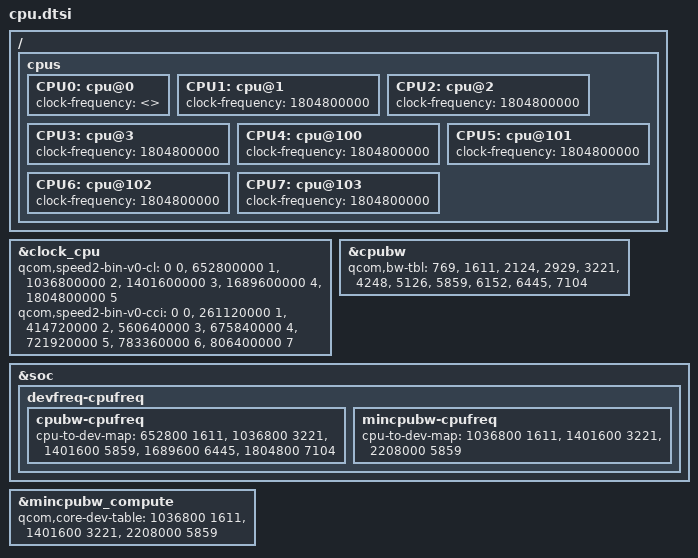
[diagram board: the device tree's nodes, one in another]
/{
	cpus {
        CPU0: cpu@0 {
    			clock-frequency = <>;
  		};
        CPU1: cpu@1 {
    			clock-frequency = <1804800000>;
  		};
        CPU2: cpu@2 {
    			clock-frequency = <1804800000>;
  		};
        CPU3: cpu@3 {
    			clock-frequency = <1804800000>;
  		};
  		CPU4: cpu@100 {
    			clock-frequency = <1804800000>;
  		};
  		CPU5: cpu@101 {
    			clock-frequency = <1804800000>;
  		};
  		CPU6: cpu@102 {
    			clock-frequency = <1804800000>;
  		};
  		CPU7: cpu@103 {
    			clock-frequency = <1804800000>;
  		};
	};
};

&clock_cpu {
	qcom,speed2-bin-v0-cl =
		<          0 0>,
		<  652800000 1>,
		< 1036800000 2>,
		< 1401600000 3>,
		< 1689600000 4>,
		< 1804800000 5>;
	qcom,speed2-bin-v0-cci =
		<          0 0>,
		<  261120000 1>,
		<  414720000 2>,
		<  560640000 3>,
		<  675840000 4>,
		<  721920000 5>,
		<  783360000 6>,
		<  806400000 7>;
};

&cpubw {
	qcom,bw-tbl =
		<   769 /*  100.8 MHz */ >,
		<  1611 /*  211.2 MHz */ >,
		<  2124 /*  278.4 MHz */ >,
		<  2929 /*  384   MHz */ >,
		<  3221 /*  422.4 MHz */ >,
		<  4248 /*  556.8 MHz */ >,
		<  5126 /*  672   MHz */ >,
		<  5859 /*  768   MHz */ >,
		<  6152 /*  806.4 MHz */ >,
		<  6445 /*  844.8 MHz */ >,
		<  7104 /*  931.2 MHz */ >;
};

&soc {
	devfreq-cpufreq {
		cpubw-cpufreq {
			cpu-to-dev-map =
				<  652800  1611>,
				< 1036800  3221>,
				< 1401600  5859>,
				< 1689600  6445>,
				< 1804800  7104>;
		};
		mincpubw-cpufreq {
			cpu-to-dev-map =
				< 1036800 1611 >,
				< 1401600 3221 >,
				< 2208000 5859 >;
		};
	};
};

&mincpubw_compute {
	qcom,core-dev-table =
		< 1036800 1611 >,
		< 1401600 3221 >,
		< 2208000 5859 >;
};
